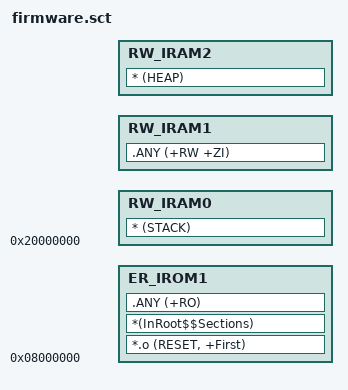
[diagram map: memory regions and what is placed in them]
; *************************************************************
; *** Scatter-Loading Description File generated by uVision ***
; *************************************************************

LR_IROM1 0x08000000 0x00010000  {    ; load region size_region
  ER_IROM1  +0 {  ; load address = execution address
   *.o (RESET, +First)
   *(InRoot$$Sections)
   .ANY (+RO)
  }
  RW_IRAM0 0x20000000 {  ; RW data
   * (STACK)
  }
  RW_IRAM1 +0 {  ; RW data
   .ANY (+RW +ZI)
  }
  RW_IRAM2 +0 {  ; RW data
   * (HEAP)
  }
}

